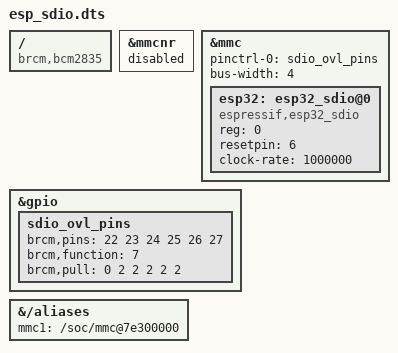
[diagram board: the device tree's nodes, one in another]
/dts-v1/;
/plugin/;

/* Enable SDIO from MMC interface via various GPIO groups */

/{
	compatible = "brcm,bcm2835";

	fragment@0 {
		target = <&mmcnr>;
		__overlay__ {
			status = "disabled";
		};
	};

	fragment@1 {
		target = <&mmc>;
		sdio_ovl: __overlay__ {
			pinctrl-0 = <&sdio_ovl_pins>;
			pinctrl-names = "default";
			bus-width = <4>;
			status = "okay";
			#address-cells = <1>;
			#size-cells = <0>;
			esp32: esp32_sdio@0 {
				reg = <0>;
				#address-cells = <1>;
				#size-cells = <0>;
				status = "okay";
				compatible = "espressif,esp32_sdio";
				resetpin = <6>;
				clock-rate = <1000000>;
			};
		};
	};

	fragment@2 {
		target = <&gpio>;
		__overlay__ {
			sdio_ovl_pins: sdio_ovl_pins {
				brcm,pins = <22 23 24 25 26 27>;
				brcm,function = <7>; /* ALT3 = SD1 */
				brcm,pull = <0 2 2 2 2 2>;
			};
		};
	};

	fragment@6 {
		target-path = "/aliases";
		__overlay__ {
			mmc1 = "/soc/mmc@7e300000";
		};
	};

};
